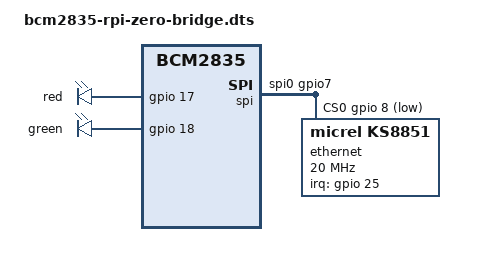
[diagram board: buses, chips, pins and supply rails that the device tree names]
// SPDX-License-Identifier: GPL-2.0+
/*
 * Rademacher Smart2Smart bridge: Raspberry Pi Zero + Micrel KS8851 on SPI0.
 *
 * Values taken from the stock firmware's bcm2835-rpi-zero.dtb:
 *   - ks8851 on spi0 CS0 (GPIO8), interrupt GPIO25 (falling edge), 20 MHz
 *   - no MAC address here: /usr/libexec/default-mac derives one from the board serial (see GOTCHAS.md)
 *
 * The PL011 UART (ttyAMA0, GPIO14/15) is left enabled by the base DTS; on this
 * board it talks to the RL78 radio controller, so no console is put on it.
 */

#include <dt-bindings/gpio/gpio.h>
#include <dt-bindings/interrupt-controller/irq.h>
#include "broadcom/bcm2835-rpi-zero.dts"

/ {
	/* The two LEDs on the bridge PCB, as in the stock device tree. */
	bridge-leds {
		compatible = "gpio-leds";

		led-red {
			label = "red";
			gpios = <&gpio 17 GPIO_ACTIVE_HIGH>;
			linux,default-trigger = "heartbeat";
		};

		led-green {
			label = "green";
			gpios = <&gpio 18 GPIO_ACTIVE_HIGH>;
			default-state = "on";
			/* stays on as in the stock firmware, blinks at 2 Hz while the kernel is in a panic */
			panic-indicator;
		};
	};
};

&gpio {
	/*
	 * The base DTS puts GPIO4-11 in ALT0 and GPIO18-21 in I2S as the GPIO controller's own default state.
	 * That includes the SPI0 pins (the KS8851 would never probe: "pin gpio7 already requested") and the
	 * green LED on GPIO18. Keep only the group that is really needed.
	 */
	pinctrl-0 = <&gpioout>;

	ks8851_pins: ks8851-pins {
		brcm,pins = <25>;
		brcm,function = <BCM2835_FSEL_GPIO_IN>;
		brcm,pull = <BCM2835_PUD_OFF>;
	};
};

&spi {
	pinctrl-names = "default";
	pinctrl-0 = <&spi0_gpio7>;
	cs-gpios = <&gpio 8 GPIO_ACTIVE_LOW>,
		   <&gpio 7 GPIO_ACTIVE_LOW>;
	status = "okay";

	ethernet@0 {
		compatible = "micrel,ks8851";
		reg = <0>;
		pinctrl-names = "default";
		pinctrl-0 = <&ks8851_pins>;
		interrupt-parent = <&gpio>;
		interrupts = <25 IRQ_TYPE_EDGE_FALLING>;
		spi-max-frequency = <20000000>;
	};
};
